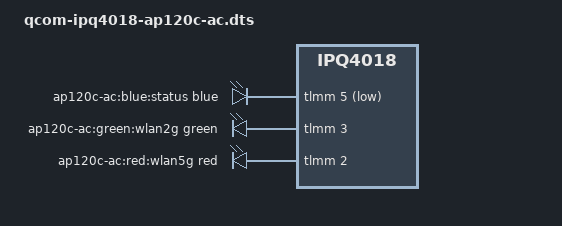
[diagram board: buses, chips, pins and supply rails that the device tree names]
// SPDX-License-Identifier: GPL-2.0-or-later OR MIT

#include <dt-bindings/leds/common.h>
#include "qcom-ipq4018-ap120c-ac.dtsi"

/ {
	leds {
		compatible = "gpio-leds";

		status: status {
			label = "ap120c-ac:blue:status";
			function = LED_FUNCTION_STATUS;
			color = <LED_COLOR_ID_BLUE>;
			gpios = <&tlmm 5 GPIO_ACTIVE_LOW>;
			default-state = "keep";
		};

		wlan2g {
			label = "ap120c-ac:green:wlan2g";
			function = LED_FUNCTION_WLAN;
			color = <LED_COLOR_ID_GREEN>;
			gpios = <&tlmm 3 GPIO_ACTIVE_HIGH>;
			linux,default-trigger = "phy0tpt";
		};

		wlan5g {
			label = "ap120c-ac:red:wlan5g";
			function = LED_FUNCTION_WLAN;
			color = <LED_COLOR_ID_RED>;
			gpios = <&tlmm 2 GPIO_ACTIVE_HIGH>;
			linux,default-trigger = "phy1tpt";
		};
	};
};
